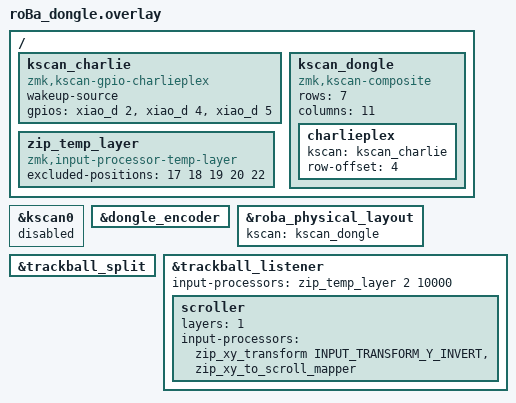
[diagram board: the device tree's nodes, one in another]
#include "roBa.dtsi"
#include "roBa_trackball.dtsi"
#include <input/processors.dtsi>
#include <dt-bindings/zmk/input_transform.h>

/ {
    kscan_charlie: kscan_charlie {
        compatible = "zmk,kscan-gpio-charlieplex";
        wakeup-source;
        gpios
            = <&xiao_d 2 GPIO_ACTIVE_HIGH>
            , <&xiao_d 4 GPIO_ACTIVE_HIGH>
            , <&xiao_d 5 GPIO_ACTIVE_HIGH>
            ;
    };

    kscan_dongle: kscan_dongle {
        compatible = "zmk,kscan-composite";
        rows = <7>;
        columns = <11>;

        charlieplex {
            kscan = <&kscan_charlie>;
            row-offset = <4>;
        };
    };
};

&kscan0 {
    status = "disabled";
};

&dongle_encoder {
    status = "okay";
};

&roba_physical_layout {
    kscan = <&kscan_dongle>;
};

/ {
    zip_temp_layer: zip_temp_layer {
        compatible = "zmk,input-processor-temp-layer";
        #input-processor-cells = <2>;
        excluded-positions = <
            17 // H
            18 // J
            19 // K
            20 // L
            22 // Z
        >;
    };
};

&trackball_split {
    status = "okay";
};

&trackball_listener {
    status = "okay";

    input-processors = <&zip_temp_layer 2 10000>;

    scroller {
        layers = <1>;
        input-processors =
            <&zip_xy_transform INPUT_TRANSFORM_Y_INVERT>,
            <&zip_xy_to_scroll_mapper>;
    };
};
